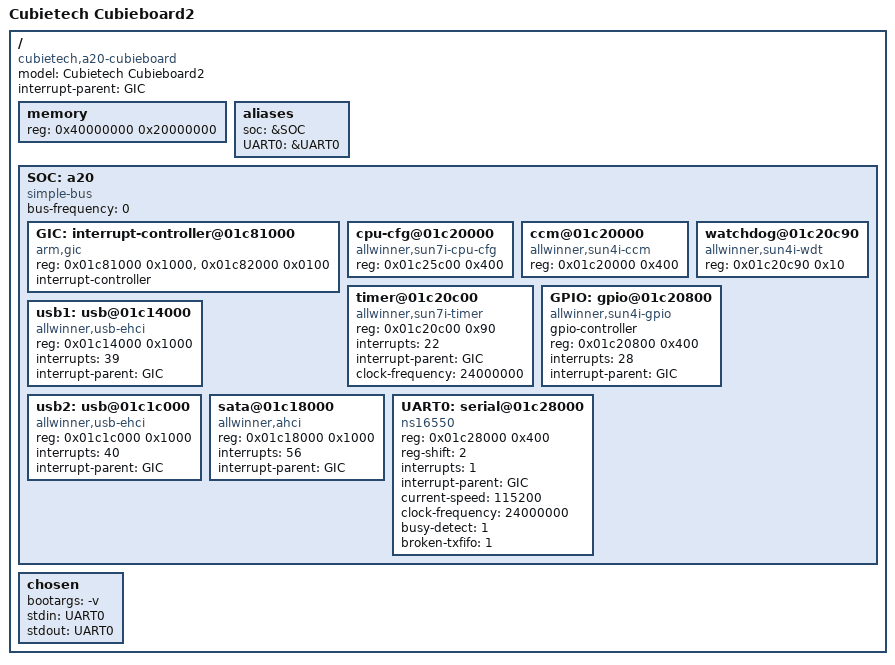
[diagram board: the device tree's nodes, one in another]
/*-
 * Copyright (c) 2013 Ganbold Tsagaankhuu <ganbold@gmail.com>
 * All rights reserved.
 *
 * Redistribution and use in source and binary forms, with or without
 * modification, are permitted provided that the following conditions
 * are met:
 * 1. Redistributions of source code must retain the above copyright
 *    notice, this list of conditions and the following disclaimer.
 * 2. Redistributions in binary form must reproduce the above copyright
 *    notice, this list of conditions and the following disclaimer in the
 *    documentation and/or other materials provided with the distribution.
 *
 * THIS SOFTWARE IS PROVIDED BY THE AUTHOR AND CONTRIBUTORS ``AS IS'' AND
 * ANY EXPRESS OR IMPLIED WARRANTIES, INCLUDING, BUT NOT LIMITED TO, THE
 * IMPLIED WARRANTIES OF MERCHANTABILITY AND FITNESS FOR A PARTICULAR PURPOSE
 * ARE DISCLAIMED.  IN NO EVENT SHALL THE AUTHOR OR CONTRIBUTORS BE LIABLE
 * FOR ANY DIRECT, INDIRECT, INCIDENTAL, SPECIAL, EXEMPLARY, OR CONSEQUENTIAL
 * DAMAGES (INCLUDING, BUT NOT LIMITED TO, PROCUREMENT OF SUBSTITUTE GOODS
 * OR SERVICES; LOSS OF USE, DATA, OR PROFITS; OR BUSINESS INTERRUPTION)
 * HOWEVER CAUSED AND ON ANY THEORY OF LIABILITY, WHETHER IN CONTRACT, STRICT
 * LIABILITY, OR TORT (INCLUDING NEGLIGENCE OR OTHERWISE) ARISING IN ANY WAY
 * OUT OF THE USE OF THIS SOFTWARE, EVEN IF ADVISED OF THE POSSIBILITY OF
 * SUCH DAMAGE.
 * 
 * $FreeBSD$
 */

/dts-v1/;

/ {
	model = "Cubietech Cubieboard2";
	compatible = "cubietech,a20-cubieboard", "allwinner,sun7i-a20";
	#address-cells = <1>;
	#size-cells = <1>;

	interrupt-parent = <&GIC>;

	memory {
		device_type = "memory";
		reg = < 0x40000000 0x20000000 >;	/* 512MB RAM */
	};

	aliases {
		soc = &SOC;
		UART0 = &UART0;
	};

	SOC: a20 {
		#address-cells = <1>;
		#size-cells = <1>;
		compatible = "simple-bus";
		ranges;
		bus-frequency = <0>;

		GIC: interrupt-controller@01c81000 {
			compatible = "arm,gic";
			reg = 	<0x01c81000 0x1000>,	/* Distributor Registers */
				<0x01c82000 0x0100>;	/* CPU Interface Registers */
			interrupt-controller;
			#interrupt-cells = <1>;
		};

		cpu-cfg@01c20000 {
			compatible = "allwinner,sun7i-cpu-cfg";
			#address-cells = <1>;
			#size-cells = <1>;
			reg = < 0x01c25c00 0x400 >;
		};

		ccm@01c20000 {
			compatible = "allwinner,sun4i-ccm";
			#address-cells = <1>;
			#size-cells = <1>;
			reg = < 0x01c20000 0x400 >;
		};

		timer@01c20c00 {
			compatible = "allwinner,sun7i-timer";
			reg = <0x01c20c00 0x90>;
			interrupts = < 22 >;
			interrupt-parent = <&GIC>;
			clock-frequency = < 24000000 >;
		};

		watchdog@01c20c90 {
			compatible = "allwinner,sun4i-wdt";
			reg = <0x01c20c90 0x10>;
		};

		GPIO: gpio@01c20800 {
			#gpio-cells = <3>;
			compatible = "allwinner,sun4i-gpio";
			gpio-controller;
			reg =<  0x01c20800 0x400 >;
			interrupts = < 28 >;
			interrupt-parent = <&GIC>;
		};

		usb1: usb@01c14000 {
			compatible = "allwinner,usb-ehci", "usb-ehci";
			reg = <0x01c14000 0x1000>;
			interrupts = < 39 >;
			interrupt-parent = <&GIC>;
		};

		usb2: usb@01c1c000 {
			compatible = "allwinner,usb-ehci", "usb-ehci";
			reg = <0x01c1c000 0x1000>;
			interrupts = < 40 >;
			interrupt-parent = <&GIC>;
		};

		sata@01c18000 {
			compatible = "allwinner,ahci";
			reg = <0x01c18000 0x1000>;
			interrupts = <56>;
			interrupt-parent = <&GIC>;
		};

		UART0: serial@01c28000 {
			status = "okay";
			compatible = "ns16550";
			reg = <0x01c28000 0x400>;
			reg-shift = <2>;
			interrupts = <1>;
			interrupt-parent = <&GIC>;
			current-speed = <115200>;
			clock-frequency = < 24000000 >;
			busy-detect = <1>;
			broken-txfifo = <1>;
		};
	};

	chosen {
		bootargs = "-v";
		stdin = "UART0";
		stdout = "UART0";
	};
};

